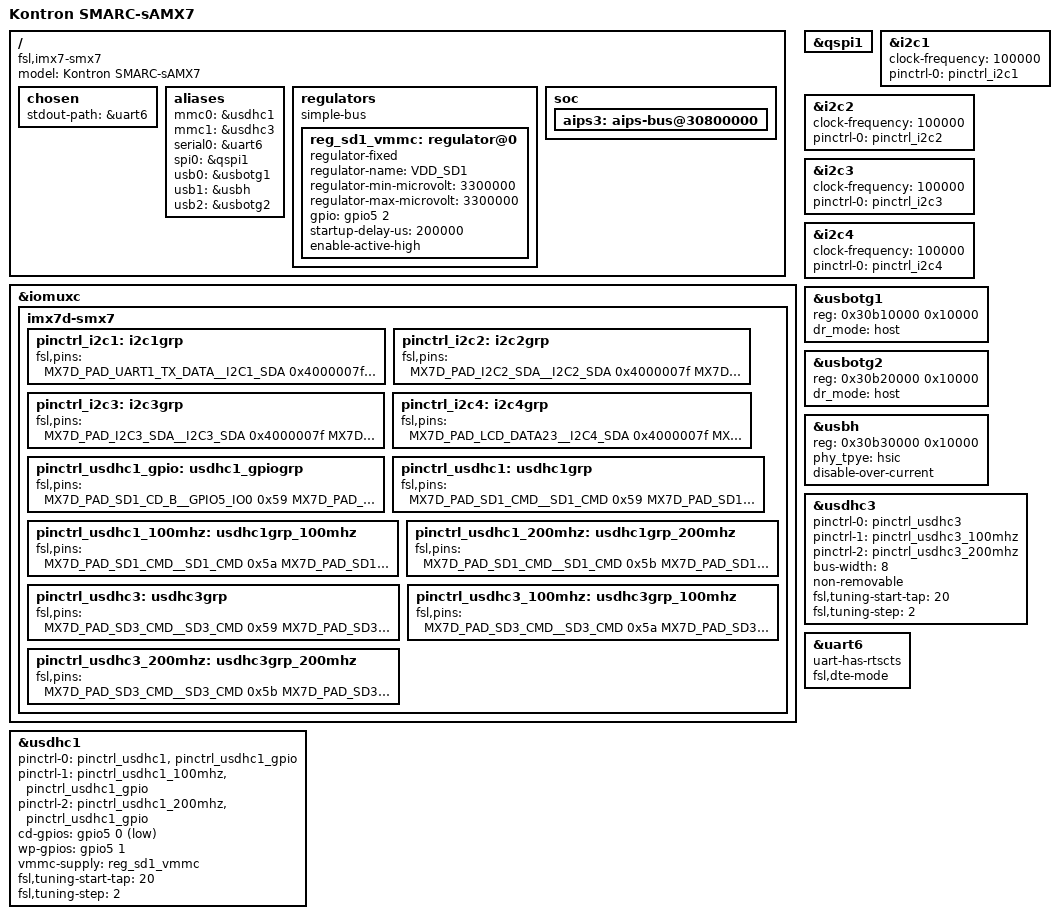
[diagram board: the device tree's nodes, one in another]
// SPDX-License-Identifier: GPL-2.0+ OR X11
/*
 * Copyright 2019 Kontron Europe GmbH
 */

/dts-v1/;
#include "imx7d.dtsi"

/ {
	model = "Kontron SMARC-sAMX7";
	compatible = "fsl,imx7-smx7", "fsl,imx7d";

        chosen {
                stdout-path = &uart6;
        };

	aliases {
		mmc0 = &usdhc1;
		mmc1 = &usdhc3; 
                serial0 = &uart6;
		spi0 = &qspi1;
                usb0 = &usbotg1;
                usb1 = &usbh;
                usb2 = &usbotg2;
	};

	regulators {
		compatible = "simple-bus";

		reg_sd1_vmmc: regulator@0 {
			compatible = "regulator-fixed";
			regulator-name = "VDD_SD1";
			regulator-min-microvolt = <3300000>;
			regulator-max-microvolt = <3300000>;
			gpio = <&gpio5 2 GPIO_ACTIVE_HIGH>;
			startup-delay-us = <200000>;
			enable-active-high;
		};
	};

	soc {
		u-boot,dm-spl;
		aips3: aips-bus@30800000{
			u-boot,dm-spl;
		};
	};
};

&iomuxc {
	imx7d-smx7 {
		pinctrl_i2c1: i2c1grp {
			fsl,pins = <
				MX7D_PAD_UART1_TX_DATA__I2C1_SDA	0x4000007f
				MX7D_PAD_UART1_RX_DATA__I2C1_SCL        0x4000007f
			>;
		};

		pinctrl_i2c2: i2c2grp {
			fsl,pins = <
				MX7D_PAD_I2C2_SDA__I2C2_SDA	0x4000007f
				MX7D_PAD_I2C2_SCL__I2C2_SCL	0x4000007f
			>;
		};

		pinctrl_i2c3: i2c3grp {
			fsl,pins = <
				MX7D_PAD_I2C3_SDA__I2C3_SDA	0x4000007f
				MX7D_PAD_I2C3_SCL__I2C3_SCL	0x4000007f
			>;
		};

		pinctrl_i2c4: i2c4grp {
			fsl,pins = <
				MX7D_PAD_LCD_DATA23__I2C4_SDA	0x4000007f
				MX7D_PAD_LCD_DATA22__I2C4_SCL	0x4000007f
			>;
		};

		pinctrl_usdhc1_gpio: usdhc1_gpiogrp {
			fsl,pins = <
				MX7D_PAD_SD1_CD_B__GPIO5_IO0		0x59 /* CD */
				MX7D_PAD_SD1_WP__GPIO5_IO1		0x59 /* WP */
				MX7D_PAD_SD1_RESET_B__GPIO5_IO2		0x59 /* vmmc */
			>;
		};

		pinctrl_usdhc1: usdhc1grp {
			fsl,pins = <
				MX7D_PAD_SD1_CMD__SD1_CMD		0x59
				MX7D_PAD_SD1_CLK__SD1_CLK		0x19
				MX7D_PAD_SD1_DATA0__SD1_DATA0		0x59
				MX7D_PAD_SD1_DATA1__SD1_DATA1		0x59
				MX7D_PAD_SD1_DATA2__SD1_DATA2		0x59
				MX7D_PAD_SD1_DATA3__SD1_DATA3		0x59
			>;
		};

		pinctrl_usdhc1_100mhz: usdhc1grp_100mhz {
			fsl,pins = <
				MX7D_PAD_SD1_CMD__SD1_CMD		0x5a
				MX7D_PAD_SD1_CLK__SD1_CLK		0x1a
				MX7D_PAD_SD1_DATA0__SD1_DATA0		0x5a
				MX7D_PAD_SD1_DATA1__SD1_DATA1		0x5a
				MX7D_PAD_SD1_DATA2__SD1_DATA2		0x5a
				MX7D_PAD_SD1_DATA3__SD1_DATA3		0x5a
			>;
		};

		pinctrl_usdhc1_200mhz: usdhc1grp_200mhz {
			fsl,pins = <
				MX7D_PAD_SD1_CMD__SD1_CMD		0x5b
				MX7D_PAD_SD1_CLK__SD1_CLK		0x1b
				MX7D_PAD_SD1_DATA0__SD1_DATA0		0x5b
				MX7D_PAD_SD1_DATA1__SD1_DATA1		0x5b
				MX7D_PAD_SD1_DATA2__SD1_DATA2		0x5b
				MX7D_PAD_SD1_DATA3__SD1_DATA3		0x5b
			>;
		};

		pinctrl_usdhc3: usdhc3grp {
			fsl,pins = <
				MX7D_PAD_SD3_CMD__SD3_CMD		0x59
				MX7D_PAD_SD3_CLK__SD3_CLK		0x19
				MX7D_PAD_SD3_DATA0__SD3_DATA0		0x59
				MX7D_PAD_SD3_DATA1__SD3_DATA1		0x59
				MX7D_PAD_SD3_DATA2__SD3_DATA2		0x59
				MX7D_PAD_SD3_DATA3__SD3_DATA3		0x59
				MX7D_PAD_SD3_DATA4__SD3_DATA4		0x59
				MX7D_PAD_SD3_DATA5__SD3_DATA5		0x59
				MX7D_PAD_SD3_DATA6__SD3_DATA6		0x59
				MX7D_PAD_SD3_DATA7__SD3_DATA7		0x59
				MX7D_PAD_SD3_STROBE__SD3_STROBE         0x19
			>;
		};

		pinctrl_usdhc3_100mhz: usdhc3grp_100mhz {
			fsl,pins = <
				MX7D_PAD_SD3_CMD__SD3_CMD		0x5a
				MX7D_PAD_SD3_CLK__SD3_CLK		0x1a
				MX7D_PAD_SD3_DATA0__SD3_DATA0		0x5a
				MX7D_PAD_SD3_DATA1__SD3_DATA1		0x5a
				MX7D_PAD_SD3_DATA2__SD3_DATA2		0x5a
				MX7D_PAD_SD3_DATA3__SD3_DATA3		0x5a
				MX7D_PAD_SD3_DATA4__SD3_DATA4		0x5a
				MX7D_PAD_SD3_DATA5__SD3_DATA5		0x5a
				MX7D_PAD_SD3_DATA6__SD3_DATA6		0x5a
				MX7D_PAD_SD3_DATA7__SD3_DATA7		0x5a
				MX7D_PAD_SD3_STROBE__SD3_STROBE		0x1a
			>;
		};

		pinctrl_usdhc3_200mhz: usdhc3grp_200mhz {
			fsl,pins = <
				MX7D_PAD_SD3_CMD__SD3_CMD		0x5b
				MX7D_PAD_SD3_CLK__SD3_CLK		0x1b
				MX7D_PAD_SD3_DATA0__SD3_DATA0		0x5b
				MX7D_PAD_SD3_DATA1__SD3_DATA1		0x5b
				MX7D_PAD_SD3_DATA2__SD3_DATA2		0x5b
				MX7D_PAD_SD3_DATA3__SD3_DATA3		0x5b
				MX7D_PAD_SD3_DATA4__SD3_DATA4		0x5b
				MX7D_PAD_SD3_DATA5__SD3_DATA5		0x5b
				MX7D_PAD_SD3_DATA6__SD3_DATA6		0x5b
				MX7D_PAD_SD3_DATA7__SD3_DATA7		0x5b
				MX7D_PAD_SD3_STROBE__SD3_STROBE		0x1b
			>;
		};
	};
};

&qspi1 {
	u-boot,dm-spl;
	status = "okay";
};

&i2c1 {
	clock-frequency = <100000>;
	pinctrl-names = "default";
	pinctrl-0 = <&pinctrl_i2c1>;
	status = "okay";
};

&i2c2 {
	clock-frequency = <100000>;
	pinctrl-names = "default";
	pinctrl-0 = <&pinctrl_i2c2>;
	status = "okay";
};

&i2c3 {
	clock-frequency = <100000>;
	pinctrl-names = "default";
	pinctrl-0 = <&pinctrl_i2c3>;
	status = "okay";
};

&i2c4 {
	clock-frequency = <100000>;
	pinctrl-names = "default";
	pinctrl-0 = <&pinctrl_i2c4>;
	status = "okay";
};

&usbotg1 {
	reg = <0x30b10000 0x10000>;
	dr_mode = "host";
	status = "okay";
};

&usbotg2 {
	reg = <0x30b20000 0x10000>;
	dr_mode = "host";
	status = "okay";
};

&usbh {
	reg = <0x30b30000 0x10000>;
	phy_tpye = "hsic";
	disable-over-current;
	status = "okay";
};

&usdhc1 {
	pinctrl-names = "default", "state_100mhz", "state_200mhz";
	pinctrl-0 = <&pinctrl_usdhc1>, <&pinctrl_usdhc1_gpio>;
	pinctrl-1 = <&pinctrl_usdhc1_100mhz>, <&pinctrl_usdhc1_gpio>;
	pinctrl-2 = <&pinctrl_usdhc1_200mhz>, <&pinctrl_usdhc1_gpio>;
	cd-gpios = <&gpio5 0 GPIO_ACTIVE_LOW>;
	wp-gpios = <&gpio5 1 GPIO_ACTIVE_HIGH>;
	vmmc-supply = <&reg_sd1_vmmc>;
	fsl,tuning-start-tap = <20>;
	fsl,tuning-step = <2>;
	status = "okay";
};

&usdhc3 {
	pinctrl-names = "default", "state_100mhz", "state_200mhz";
	pinctrl-0 = <&pinctrl_usdhc3>;
	pinctrl-1 = <&pinctrl_usdhc3_100mhz>;
	pinctrl-2 = <&pinctrl_usdhc3_200mhz>;
	bus-width = <8>;
	non-removable;
	fsl,tuning-start-tap = <20>;
	fsl,tuning-step = <2>;
	status = "okay";
};

&uart6 {
	uart-has-rtscts;
        fsl,dte-mode;
	status = "okay";
};
